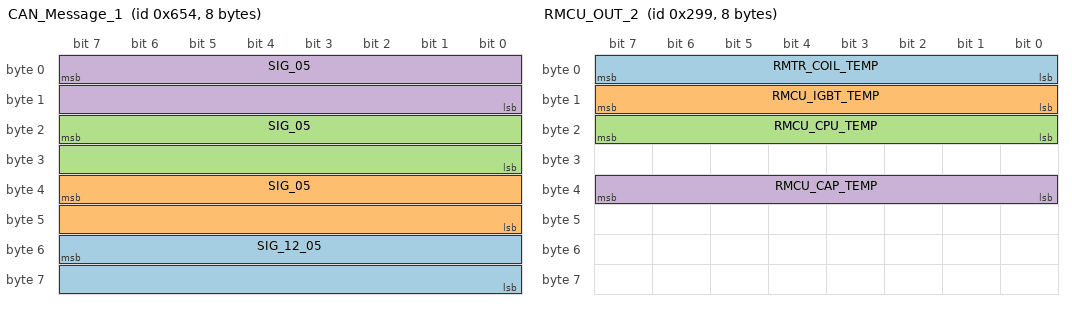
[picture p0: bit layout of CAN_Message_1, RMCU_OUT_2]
BO_ 1620 CAN_Message_1: 8 BCM
 SG_ SIG_12_05 : 55|16@0+ (0.001,0) [0|5] "V"  ECU,BCM
 SG_ SIG_05 : 39|16@0+ (0.001,0) [0|5] "V"  ECU,BCM
 SG_ SIG_05 : 23|16@0+ (0.001,0) [0|5] "V"  ECU,BCM
 SG_ SIG_05 : 7|16@0+ (0.001,0) [0|5] "V"  ECU,BCM

BO_ 665 RMCU_OUT_2: 8 RMCU
 SG_ RMTR_COIL_TEMP : 0|8@1+ (1,-40) [-40|200] "deg_C"  TCU,PHEV
 SG_ RMCU_IGBT_TEMP : 8|8@1+ (1,-40) [-40|200] "deg_C"  TCU,PHEV
 SG_ RMCU_CPU_TEMP : 16|8@1+ (1,-40) [-40|200] "deg_C"  TCU,PHEV
 SG_ RMCU_CAP_TEMP : 32|8@1+ (1,-40) [-40|200] "deg_C"  TCU,PHEV

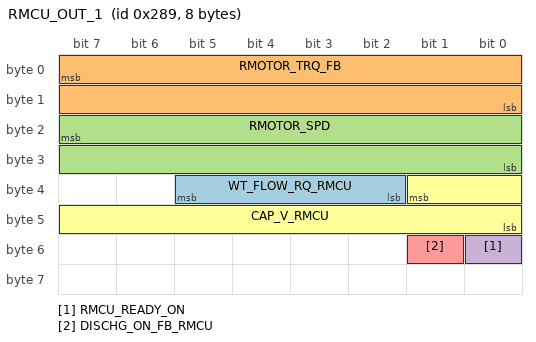
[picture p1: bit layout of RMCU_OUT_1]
BO_ 649 RMCU_OUT_1: 8 RMCU
 SG_ WT_FLOW_RQ_RMCU : 34|4@1+ (1,0) [0|10] "L"  TCU,PHEV
 SG_ RMOTOR_TRQ_FB : 7|16@0+ (0.1,-1000) [-1000|1000] "Nm"  TCU,PHEV
 SG_ RMOTOR_SPD : 23|16@0+ (1,-20000) [-20000|20000] "rpm"  BMU,PHEV
 SG_ RMCU_READY_ON : 48|1@1+ (1,0) [0|0] ""  PHEV
 SG_ DISCHG_ON_FB_RMCU : 49|1@1+ (1,0) [0|0] ""  TCU,PHEV
 SG_ CAP_V_RMCU : 33|10@0+ (1,0) [0|1000] "V"  TCU,PHEV
